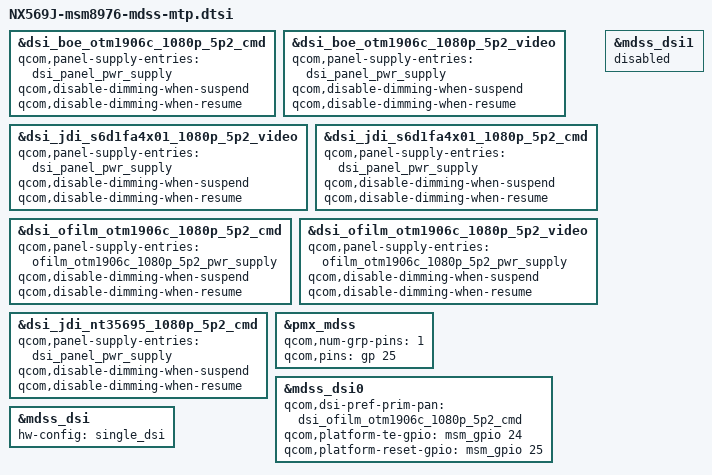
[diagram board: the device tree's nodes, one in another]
/*
 * Copyright (c) 2015-2016, The Linux Foundation. All rights reserved.
 *
 * This program is free software; you can redistribute it and/or modify
 * it under the terms of the GNU General Public License version 2 and
 * only version 2 as published by the Free Software Foundation.
 *
 * This program is distributed in the hope that it will be useful,
 * but WITHOUT ANY WARRANTY; without even the implied warranty of
 * MERCHANTABILITY or FITNESS FOR A PARTICULAR PURPOSE.  See the
 * GNU General Public License for more details.
 */


&dsi_boe_otm1906c_1080p_5p2_cmd {
	qcom,panel-supply-entries = <&dsi_panel_pwr_supply>;
	qcom,disable-dimming-when-suspend;
	qcom,disable-dimming-when-resume;
};

&dsi_boe_otm1906c_1080p_5p2_video {
	qcom,panel-supply-entries = <&dsi_panel_pwr_supply>;
	qcom,disable-dimming-when-suspend;
	qcom,disable-dimming-when-resume;
};

&dsi_jdi_s6d1fa4x01_1080p_5p2_video {
	qcom,panel-supply-entries = <&dsi_panel_pwr_supply>;
	qcom,disable-dimming-when-suspend;
	qcom,disable-dimming-when-resume;
};

&dsi_jdi_s6d1fa4x01_1080p_5p2_cmd {
	qcom,panel-supply-entries = <&dsi_panel_pwr_supply>;
	qcom,disable-dimming-when-suspend;
	qcom,disable-dimming-when-resume;
};


&dsi_ofilm_otm1906c_1080p_5p2_cmd {
	qcom,panel-supply-entries = <&ofilm_otm1906c_1080p_5p2_pwr_supply>;
	qcom,disable-dimming-when-suspend;
	qcom,disable-dimming-when-resume;
};

&dsi_ofilm_otm1906c_1080p_5p2_video {
	qcom,panel-supply-entries = <&ofilm_otm1906c_1080p_5p2_pwr_supply>;
	qcom,disable-dimming-when-suspend;
	qcom,disable-dimming-when-resume;
};

&dsi_jdi_nt35695_1080p_5p2_cmd {
	qcom,panel-supply-entries = <&dsi_panel_pwr_supply>;
	qcom,disable-dimming-when-suspend;
	qcom,disable-dimming-when-resume;
};

&pmx_mdss {
	qcom,num-grp-pins = <1>;
	qcom,pins = <&gp 25>;
};


&mdss_dsi0 {
	qcom,dsi-pref-prim-pan = <&dsi_ofilm_otm1906c_1080p_5p2_cmd>;

	qcom,platform-te-gpio = <&msm_gpio 24 0>;
	qcom,platform-reset-gpio = <&msm_gpio 25 0>;
	/delete-property/ qcom,platform-bklight-en-gpio;
	/delete-property/ qcom,panel-mode-gpio;
};

&mdss_dsi1 {
	status = "disabled";
};

&mdss_dsi {
	hw-config = "single_dsi";
};
